VERSION "Excel 2 DBC"

NS_ :

BS_:

BU_: Engine Gateway
VAL_TABLE_ ShiftRequest 0 "Shift_Request_Off" 1 "Shift_Request_On";
VAL_TABLE_ Gear 0 "Idle" 1 "Gear_1" 2 "Gear_2" 3 "Gear_3" 4 "Gear_4" 5 "Gear_5";
VAL_TABLE_ Status 0 "WakeUp" 1 "Running" 2 "GoSleep" 3 "Error";
VAL_TABLE_ IdleRunning 0 "Running" 1 "Idle";
VAL_TABLE_ GearLock 0 "Gear_Lock_Off" 1 "Gear_Lock_On";

BO_ 103 Ignition_Info: 2 Gateway
 SG_ StarterKey : 0|1@1+ (1,0) [0|1] "" Engine

BO_ 1307 NM_Engine: 4 Engine
 SG_ SleepInd : 12|1@1+ (1,0) [0|1] "" Vector__XXX

BO_ 1306 NM_Gateway_PowerTrain: 4 Gateway
 SG_ SleepInd : 12|1@1+ (1,0) [0|1] "" Vector__XXX

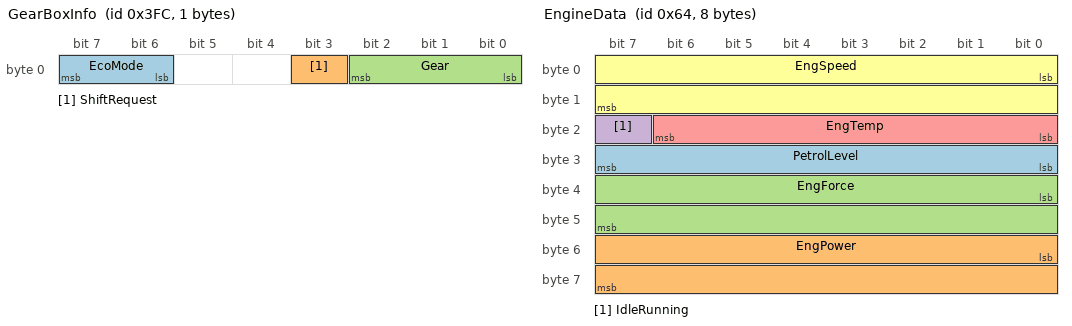
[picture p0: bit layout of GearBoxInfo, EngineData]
BO_ 1020 GearBoxInfo: 1 Engine
 SG_ EcoMode : 6|2@1+ (1,0) [0|1] "" Vector__XXX
 SG_ ShiftRequest : 3|1@1+ (1,0) [0|0] "" Vector__XXX
 SG_ Gear : 0|3@1+ (1,0) [0|5] "" Gateway

BO_ 101 EngineStatus: 1 Engine
 SG_ ErrorCode : 2|6@1+ (1,0) [0|0] "" Vector__XXX
 SG_ Status : 0|2@1+ (1,0) [0|0] "" Vector__XXX

BO_ 102 EngineDataIEEE: 8 Engine
 SG_ EngSpeed : 0|32@1+ (1,0) [0|8000] "rpm" Vector__XXX
 SG_ EngForce : 32|32@1+ (1,0) [0|0] "N" Vector__XXX

BO_ 100 EngineData: 8 Engine
 SG_ PetrolLevel : 24|8@1+ (1,0) [0|255] "l" Vector__XXX
 SG_ EngPower : 48|16@1+ (0.01,0) [0|150] "kW" Vector__XXX
 SG_ EngForce : 32|16@1+ (1,0) [0|0] "N" Vector__XXX
 SG_ IdleRunning : 23|1@1+ (1,0) [0|0] "" Vector__XXX
 SG_ EngTemp : 16|7@1+ (2,-50) [-50|150] "degC" Vector__XXX
 SG_ EngSpeed : 0|16@1+ (1,0) [0|8000] "rpm" Vector__XXX

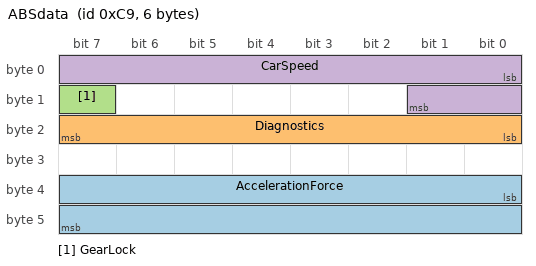
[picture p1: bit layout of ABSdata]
BO_ 201 ABSdata: 6 Engine
 SG_ AccelerationForce : 32|16@1+ (1,-10000) [0|0] "N" Vector__XXX
 SG_ Diagnostics : 16|8@1+ (1,0) [0|0] "" Vector__XXX
 SG_ GearLock : 15|1@1+ (1,0) [0|0] "" Vector__XXX
 SG_ CarSpeed : 0|10@1+ (0.5,0) [0|300] "mph" Vector__XXX

BA_DEF_ BO_ "GenMsgCycleTime" INT 0 65535;
BA_DEF_ SG_ "GenSigStartValue" FLOAT 0 100000000000;
BA_ "GenMsgCycleTime" BO_ 103 20;
BA_ "GenMsgCycleTime" BO_ 1020 50;
BA_ "GenMsgCycleTime" BO_ 102 50;
BA_ "GenMsgCycleTime" BO_ 100 50;
BA_ "GenMsgCycleTime" BO_ 201 50;
BA_ "GenSigStartValue" SG_ 100 EngTemp 25;
BA_ "GenSigStartValue" SG_ 201 AccelerationForce 10000;
VAL_ 1020 ShiftRequest 0 "Shift_Request_Off" 1 "Shift_Request_On";
VAL_ 1020 Gear 0 "Idle" 1 "Gear_1" 2 "Gear_2" 3 "Gear_3" 4 "Gear_4" 5 "Gear_5";
VAL_ 101 Status 0 "WakeUp" 1 "Running" 2 "GoSleep" 3 "Error";
VAL_ 100 IdleRunning 0 "Running" 1 "Idle";
VAL_ 201 GearLock 0 "Gear_Lock_Off" 1 "Gear_Lock_On";
